AUTOSAR XML (schema 4-0-3)
package /ComponentTypes
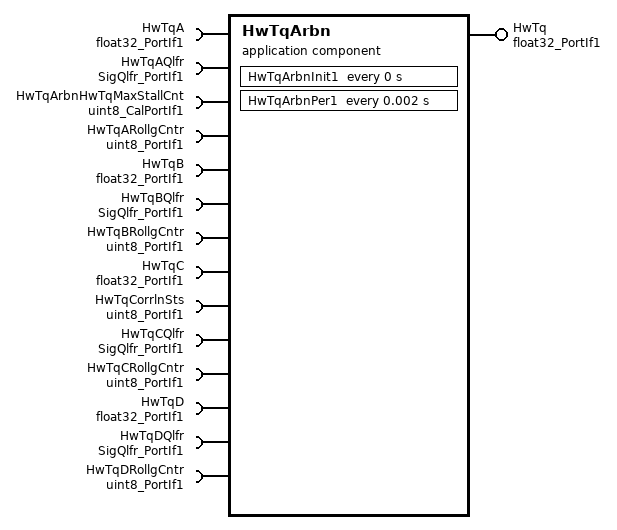
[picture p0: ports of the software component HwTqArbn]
  application sw component type HwTqArbn
    provide port HwTq: nonqueued-sender-com-spec{data-element=Val, init-value=0}, provided-interface=float32_PortIf1
    14 x require port:
      HwTqA: nonqueued-receiver-com-spec{data-element=Val, filter=data-filter-type=ALWAYS, init-value=0}, required-interface=float32_PortIf1
      HwTqAQlfr: nonqueued-receiver-com-spec{data-element=Val, filter=data-filter-type=ALWAYS, init-value=0}, required-interface=SigQlfr_PortIf1
      HwTqArbnHwTqMaxStallCnt: parameter-require-com-spec{init-value=200, parameter=Val}, required-interface=uint8_CalPortIf1
      HwTqARollgCntr: nonqueued-receiver-com-spec{data-element=Val, filter=data-filter-type=ALWAYS, init-value=0}, required-interface=uint8_PortIf1
      HwTqB: nonqueued-receiver-com-spec{data-element=Val, filter=data-filter-type=ALWAYS, init-value=0}, required-interface=float32_PortIf1
      HwTqBQlfr: nonqueued-receiver-com-spec{data-element=Val, filter=data-filter-type=ALWAYS, init-value=0}, required-interface=SigQlfr_PortIf1
      HwTqBRollgCntr: nonqueued-receiver-com-spec{data-element=Val, filter=data-filter-type=ALWAYS, init-value=0}, required-interface=uint8_PortIf1
      HwTqC: nonqueued-receiver-com-spec{data-element=Val, filter=data-filter-type=ALWAYS, init-value=0}, required-interface=float32_PortIf1
      HwTqCorrlnSts: nonqueued-receiver-com-spec{data-element=Val, filter=data-filter-type=ALWAYS, init-value=15}, required-interface=uint8_PortIf1
      HwTqCQlfr: nonqueued-receiver-com-spec{data-element=Val, filter=data-filter-type=ALWAYS, init-value=0}, required-interface=SigQlfr_PortIf1
      HwTqCRollgCntr: nonqueued-receiver-com-spec{data-element=Val, filter=data-filter-type=ALWAYS, init-value=0}, required-interface=uint8_PortIf1
      HwTqD: nonqueued-receiver-com-spec{data-element=Val, filter=data-filter-type=ALWAYS, init-value=0}, required-interface=float32_PortIf1
      HwTqDQlfr: nonqueued-receiver-com-spec{data-element=Val, filter=data-filter-type=ALWAYS, init-value=0}, required-interface=SigQlfr_PortIf1
      HwTqDRollgCntr: nonqueued-receiver-com-spec{data-element=Val, filter=data-filter-type=ALWAYS, init-value=0}, required-interface=uint8_PortIf1
    behavior HwTqArbn_InternalBehavior
      ar-typed-per-instance-memorys:
        15 x data, all with sw-calibration-access=READ-ONLY:
          dHwTqArbnAAvl: type=boolean
          dHwTqArbnBAvl: type=boolean
          dHwTqArbnCAvl: type=boolean
          dHwTqArbnDAvl: type=boolean
          dHwTqArbnHwTqDenom: type=float32
          dHwTqArbnHwTqNumer: type=float32
          HwTqARollgCntrPrev: type=uint8
          HwTqAStallCntrPrev: type=uint8
          HwTqBRollgCntrPrev: type=uint8
          HwTqBStallCntrPrev: type=uint8
          HwTqCRollgCntrPrev: type=uint8
          HwTqCStallCntrPrev: type=uint8
          HwTqDRollgCntrPrev: type=uint8
          HwTqDStallCntrPrev: type=uint8
          HwTqPrev: type=float32
      timing event HwTqArbn_InitEvent: start-on-event=HwTqArbnInit1, period=0
      timing event TMT_HwTqArbnPer1: start-on-event=HwTqArbnPer1, period=0.002
      runnable HwTqArbnInit1
      runnable HwTqArbnPer1
        data-receive-point-by-arguments:
          13 x access:
            REC_HwTqA_Val: accessed-variable=HwTqA.Val
            REC_HwTqAQlfr_Val: accessed-variable=HwTqAQlfr.Val
            REC_HwTqARollgCntr_Val: accessed-variable=HwTqARollgCntr.Val
            REC_HwTqB_Val: accessed-variable=HwTqB.Val
            REC_HwTqBQlfr_Val: accessed-variable=HwTqBQlfr.Val
            REC_HwTqBRollgCntr_Val: accessed-variable=HwTqBRollgCntr.Val
            REC_HwTqC_Val: accessed-variable=HwTqC.Val
            REC_HwTqCorrlnSts_Val: accessed-variable=HwTqCorrlnSts.Val
            REC_HwTqCQlfr_Val: accessed-variable=HwTqCQlfr.Val
            REC_HwTqCRollgCntr_Val: accessed-variable=HwTqCRollgCntr.Val
            REC_HwTqD_Val: accessed-variable=HwTqD.Val
            REC_HwTqDQlfr_Val: accessed-variable=HwTqDQlfr.Val
            REC_HwTqDRollgCntr_Val: accessed-variable=HwTqDRollgCntr.Val
        data-send-points:
          access SEND_HwTq_Val: accessed-variable=HwTq.Val
  swc implementation HwTqArbn_Implementation: behavior=HwTqArbn_InternalBehavior
    code-descriptors:
      code Default: artifact-descriptors=autosar-engineering-object={short-label=Default, category=SWSRC}
